# WB32F10x register map
File version: 1.2
CPU: CM3 r2p0, little endian, MPU, no FPU, 4 interrupt priority bits
Registers are 32-bit, read-write, reset 0x0 unless marked. A register's access mark holds for its fields unless they carry their own. Offsets are from the block's base; [hi:lo] are bit positions; 'fields as' and 'values as' point back to an identical list.

## I2C1 — Inter-Integrated Circuit 1
Base 0x40008800
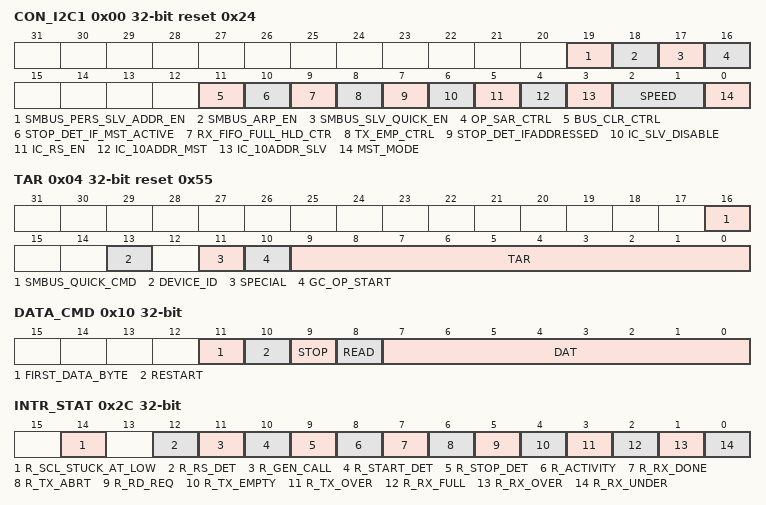
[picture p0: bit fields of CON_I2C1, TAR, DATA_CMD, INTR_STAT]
0x00 CON_I2C1 reset 0x24 — Control register for I2C1
  [19] SMBUS_PERS_SLV_ADDR_EN — SMBUS PSA enable
  [18] SMBUS_ARP_EN — SMBUS ARP enable
  [17] SMBUS_SLV_QUICK_EN — SMBUS slave quick command enable
  [16] OP_SAR_CTRL — Optional slave address control
  [11] BUS_CLR_CTRL — Bus clear control
  [10] STOP_DET_IF_MST_ACTIVE — STOP_DET interrupt enable when master is active
  [9] RX_FIFO_FULL_HLD_CTR — Hold bus when receive FIFO full control bit
  [8] TX_EMP_CTRL — Transmit empty control
  [7] STOP_DET_IFADDRESSED — STOP_DET interrupt enable when slave is addressed
  [6] IC_SLV_DISABLE — I2C slave mode disable
  [5] IC_RS_EN — I2C restart enable
  [4] IC_10ADDR_MST — I2C master 10 bits address selection
  [3] IC_10ADDR_SLV — I2C slave 10 bits address selection
  [2:1] SPEED — I2C transfer speed
  [0] MST_MODE — Master mode enable
0x04 TAR reset 0x55 — Target register
  [16] SMBUS_QUICK_CMD — SMBUS QUICK_CMD enable
  [13] DEVICE_ID — Enable DEVICE_ID
  [11] SPECIAL — Enable DEVICE_ID,GENERAL_CALL and START transfer
  [10] GC_OP_START — GENERAL CALL or START optional
  [9:0] TAR — Target address
0x08 SAR reset 0x3F0 — Slave address register
  [9:0] SAR — Slave address
0x0C HS_MADDR reset 0x1 — High speed master address register
  [2:0] HS_MAR — Master address in high speed
0x10 DATA_CMD — I2C data and command register
  [11] FIRST_DATA_BYTE
  [10] RESTART — Send restart command after transmitting
  [9] STOP — Send stop command after transmitting or receiving
  [8] READ — Master send read command
  [7:0] DAT — Data of I2C bus
0x14 SS_SCL_HCNT reset 0x320 — Standard speed clock high counter register
  [15:0] IC_SS_SCL_HCNT — SCL high level time in I2C standard speed mode
0x18 SS_SCL_LCNT reset 0x3AC — Standard speed clock low counter register
  [15:0] IC_SS_SCL_LCNT — SCL low level time in I2C standard speed mode
0x1C FS_SCL_HCNT reset 0x78 — Fast speed clock high counter register
  [15:0] IC_FS_SCL_HCNT — SCL high level time in I2C fast speed mode
0x20 FS_SCL_LCNT reset 0x104 — Fast speed clock low counter register
  [15:0] IC_FS_SCL_LCNT — SCL low level time in I2C fast speed mode
0x24 HS_SCL_HCNT reset 0xC — High speed clock high counter register
  [15:0] IC_HS_SCL_HCNT — SCL high level time in I2C high speed mode
0x28 HS_SCL_LCNT reset 0x20 — High speed clock low counter register
  [15:0] IC_HS_SCL_LCNT — SCL low level time in I2C high speed mode
0x2C INTR_STAT ro — I2C interrupt state register
  [14] R_SCL_STUCK_AT_LOW — R_SCL_STUCK_AT_LOW interrupt state
  [12] R_RS_DET — R_RS_DET interrupt state
  [11] R_GEN_CALL — R_GEN_CALL interrupt state
  [10] R_START_DET — R_START_DET interrupt state
  [9] R_STOP_DET — R_STOP_DET interrupt state
  [8] R_ACTIVITY — R_ACTIVITY interrupt state
  [7] R_RX_DONE — R_RX_DONE interrupt state
  [6] R_TX_ABRT — R_TX_ABRT interrupt state
  [5] R_RD_REQ — R_RD_REQ interrupt state
  [4] R_TX_EMPTY — R_TX_EMPTY interrupt state
  [3] R_TX_OVER — R_TX_OVER interrupt state
  [2] R_RX_FULL — R_RX_FULL interrupt state
  [1] R_RX_OVER — R_RX_OVER interrupt state
  [0] R_RX_UNDER — R_RX_UNDER interrupt state
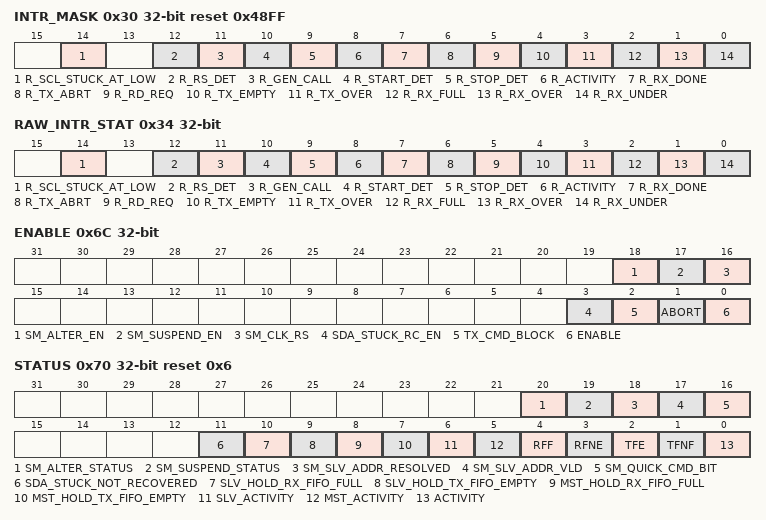
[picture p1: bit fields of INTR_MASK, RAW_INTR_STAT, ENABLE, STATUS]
0x30 INTR_MASK reset 0x48FF — I2C interrupt mask register
  [14] R_SCL_STUCK_AT_LOW — R_SCL_STUCK_AT_LOW interrupt mask
  [12] R_RS_DET — R_RS_DET interrupt mask
  [11] R_GEN_CALL — R_GEN_CALL interrupt mask
  [10] R_START_DET — R_START_DET interrupt mask
  [9] R_STOP_DET — R_STOP_DET interrupt mask
  [8] R_ACTIVITY — R_ACTIVITY interrupt mask
  [7] R_RX_DONE — R_RX_DONE interrupt mask
  [6] R_TX_ABRT — R_TX_ABRT interrupt mask
  [5] R_RD_REQ — R_RD_REQ interrupt mask
  [4] R_TX_EMPTY — R_TX_EMPTY interrupt mask
  [3] R_TX_OVER — R_TX_OVER interrupt mask
  [2] R_RX_FULL — R_RX_FULL interrupt mask
  [1] R_RX_OVER — R_RX_OVER interrupt mask
  [0] R_RX_UNDER — R_RX_UNDER interrupt mask
0x34 RAW_INTR_STAT ro — I2C raw interrupt state register
  [14] R_SCL_STUCK_AT_LOW — R_SCL_STUCK_AT_LOW interrupt raw state
  [12] R_RS_DET — R_RS_DET interrupt raw state
  [11] R_GEN_CALL — R_GEN_CALL interrupt raw state
  [10] R_START_DET — R_START_DET interrupt raw state
  [9] R_STOP_DET — R_STOP_DET interrupt raw state
  [8] R_ACTIVITY — R_ACTIVITY interrupt raw state
  [7] R_RX_DONE — R_RX_DONE interrupt raw state
  [6] R_TX_ABRT — R_TX_ABRT interrupt raw state
  [5] R_RD_REQ — R_RD_REQ interrupt raw state
  [4] R_TX_EMPTY — R_TX_EMPTY interrupt raw state
  [3] R_TX_OVER — R_TX_OVER interrupt raw state
  [2] R_RX_FULL — R_RX_FULL interrupt raw state
  [1] R_RX_OVER — R_RX_OVER interrupt raw state
  [0] R_RX_UNDER — R_RX_UNDER interrupt raw state
0x38 RX_TL reset 0x5 — Receive buffer threshold register
  [7:0] RX_TL — Receive buffer threshold
0x3C TX_TL reset 0x5 — Transmit buffer threshold register
  [7:0] TX_TL — Transmit buffer threshold
0x40 CLR_INTR ro — Clear interrupt register
  [0] CLR_INTR — Clear all interrupt states when read this bit
0x44 CLR_RX_UNDER ro — Clear RX_UNDER interrupt register
  [0] CLR_RX_UNDER — Clear RX_UNDER interrupt when read this bit
0x48 CLR_RX_OVER ro — Clear RX_OVER interrupt register
  [0] CLR_RX_OVER — Clear RX_OVER interrupt when read this bit
0x4C CLR_TX_OVER ro — Clear TX_OVER interrupt register
  [0] CLR_RX_OVER — Clear TX_OVER interrupt when read this bit
0x50 CLR_RD_REQ ro — Clear RD_REQ interrupt register
  [0] CLR_RD_REQ — Clear RD_REQ interrupt when read this bit
0x54 CLR_TX_ABRT ro — Clear TX_ABRT interrupt register
  [0] CLR_TX_ABRT — Clear TX_ABRT interrupt when read this bit
0x58 CLR_RX_DONE ro — Clear RX_DONE interrupt register
  [0] CLR_RX_DONE — Clear RX_DONE interrupt when read this bit
0x5C CLR_ACTIVITY ro — Clear TX_OVER interrupt register
  [0] CLR_ACTIVITY — Clear ACTIVITY interrupt when read this bit and I2C is not in active state
0x60 CLR_STOP_DET ro — Clear STOP_DET interrupt register
  [0] CLR_STOP_DET — Clear STOP_DET interrupt when read this bit
0x64 CLR_START_DET ro — Clear START_DET interrupt register
  [0] CLR_START_DET — Clear START_DET interrupt when read this bit
0x68 CLR_GEN_CALL ro — Clear GEN_CALL interrupt register
  [0] CLR_GEN_CALL — Clear GEN_CALL interrupt when read this bit
0x6C ENABLE — I2C enable register
  [18] SM_ALTER_EN — SMBUS alerter enable
  [17] SM_SUSPEND_EN — SMBUS suspend enable
  [16] SM_CLK_RS — SMBUS clock reset
  [3] SDA_STUCK_RC_EN — Recover SDA bus enable when SDA bus stuck in low level
  [2] TX_CMD_BLOCK — Block I2C bus transfer
  [1] ABORT — Abort transfer in master mode by setting this bit
  [0] ENABLE — Enable I2C
0x70 STATUS ro reset 0x6 — I2C status register
  [20] SM_ALTER_STATUS — SMBUS alerter satus
  [19] SM_SUSPEND_STATUS — SMBUS suspend status
  [18] SM_SLV_ADDR_RESOLVED — SMBUS slave address resolved
  [17] SM_SLV_ADDR_VLD — SMBUS slave address valuable
  [16] SM_QUICK_CMD_BIT — SMBUS QUICK CMD control
  [11] SDA_STUCK_NOT_RECOVERED — SDA status after recover
  [10] SLV_HOLD_RX_FIFO_FULL — Slave hold bus when receive FIFO is full
  [9] SLV_HOLD_TX_FIFO_EMPTY — Slave hold bus when transmit FIFO is empty
  [8] MST_HOLD_RX_FIFO_FULL — Master hold bus when receive FIFO is full
  [7] MST_HOLD_TX_FIFO_EMPTY — Master hold bus when transmit FIFO is empty
  [6] SLV_ACTIVITY — Slave activity status
  [5] MST_ACTIVITY — Master activity status
  [4] RFF — Receive buffer full
  [3] RFNE — Receive buffer not empty
  [2] TFE — Transmit buffer empty
  [1] TFNF — Transmit buffer not full
  [0] ACTIVITY — I2C activity status
0x74 TXFLR ro — Transmit buffer level register
  [2:0] TXFLR — Data numbers of transmit buffer
0x78 RXFLR ro — Receive buffer level register
  [2:0] RXFLR — Data numbers of Receive buffer
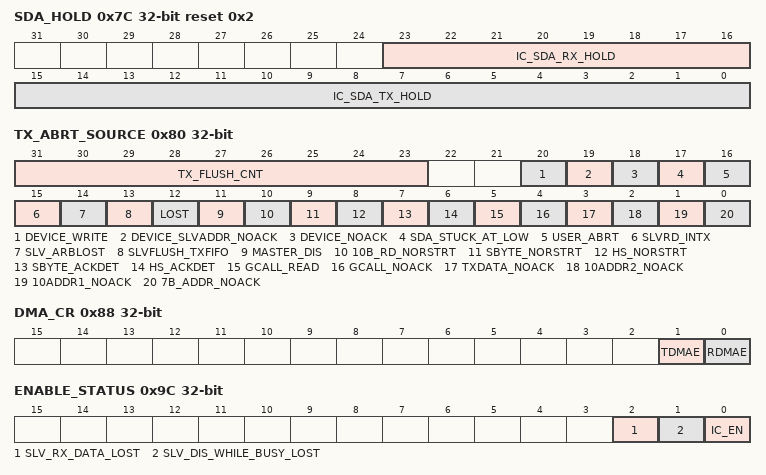
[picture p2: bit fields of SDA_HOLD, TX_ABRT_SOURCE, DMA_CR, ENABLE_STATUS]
0x7C SDA_HOLD reset 0x2
  [23:16] IC_SDA_RX_HOLD — SDA hold time in receive mode
  [15:0] IC_SDA_TX_HOLD — SDA hold time in transmit mode
0x80 TX_ABRT_SOURCE ro — Transmit abort source register
  [31:23] TX_FLUSH_CNT — Number of data lost because of TX_ABRT interrupt
  [20] DEVICE_WRITE — Other commands remain in Transmit FIFO when master start a DEVICE_ID transfer
  [19] DEVICE_SLVADDR_NOACK — No ACK from addressed slave for master's DEVICE_ID transfer
  [18] DEVICE_NOACK — No ACK for master's DEVICE_ID transfer
  [17] SDA_STUCK_AT_LOW — SDA stucks at low level for several ic_clk cycles which is specified in related register
  [16] USER_ABRT — Transfer abort
  [15] SLVRD_INTX — Write 1 into DATA_CMD.READ when slave receive a read request from master
  [14] SLV_ARBLOST — BUS arbitration lost when slave is transmitting
  [13] SLVFLUSH_TXFIFO — Data remains in transmit FIFO when slave receive a read request
  [12] LOST — BUS arbitration failure
  [11] MASTER_DIS — Master is disable when asked to transmit
  [10] 10B_RD_NORSTRT — Read data in 10 bits address mode when RESTART is disable
  [9] SBYTE_NORSTRT — RESTART is disable when master is sending START
  [8] HS_NORSTRT — RESTART is disable when master is switching to HS mode
  [7] SBYTE_ACKDET — ACK for master's sending START
  [6] HS_ACKDET — ACK for master's sending HS code
  [5] GCALL_READ — READ command after sending GCALL
  [4] GCALL_NOACK — No ACK for sending GCALL
  [3] TXDATA_NOACK — No ACK for transmitting data
  [2] 10ADDR2_NOACK — No ACK for second address byte in 10 bits address mode
  [1] 10ADDR1_NOACK — No ACK for first address byte in 10 bits address mode
  [0] 7B_ADDR_NOACK — No ACK in 7 bits address mode
0x84 SLV_DATA_NACK_ONLY — Slave data NACK register
  [0] NACK — Generate NACK
0x88 DMA_CR — DMA control register
  [1] TDMAE — Transmit DMA enable
  [0] RDMAE — Receive DMA enable
0x8C DMA_TDLR — DMA transmit data level register
  [2:0] DMATDL — DMA transmit data level
0x90 DMA_RDLR — DMA receive data level register
  [2:0] DMARDL — DMA receive data level
0x94 SDA_SETUP — SDA set-up time register
  [7:0] SDA_SETUP — SDA set-up time
0x98 ACK_GENERAL_CALL reset 0x64
  [0] ACK_GENERAL_CALL — ACK/NACK for a general all
0x9C ENABLE_STATUS ro
  [2] SLV_RX_DATA_LOST — Slave lost receive data
  [1] SLV_DIS_WHILE_BUSY_LOST — Slave disable while busy lost
  [0] IC_EN — I2C enable status
0xA0 FS_SPKLEN1 reset 0x1 — Fast speed spike length register for I2C1
  [7:0] IC_FS_SPKLEN — Max spike value on SCL and SDA line in standard and fast speed mode
0xA4 HS_SPKLEN reset 0x1 — High speed spike length register
  [7:0] IC_FS_SPKLEN — Max spike value on SCL and SDA line in high speed mode
0xA8 CLR_RESTART_DET ro — Clear RESTART_DET interrupt register
  [0] CLR_RS_DET — Clear RESTART_DET interrupt when user reads this bit
0xAC SCL_STUCK_AT_LOW_TIMEOUT reset 0xFFFFFFFF — SCl stuck at low level timeout register
  [31:0] SCL_LOWTO — Timeout threshold for SCL_STUCK_AT_LOW interrupt
0xB0 SDA_STUCK_AT_LOW_TIMEOUT reset 0xFFFFFFFF — SDA stuck at low level timeout register
  [31:0] SDA_LOWTO — Timeout threshold for SDA
0xBC SMBUS_CLK_LOW_SEXT reset 0xFFFFFFFF — SMBUS clock low slave extend timeout register
  [31:0] SMBUS_CLK_LOW_SEXT_TO — Define a paragram of SMBUS
0xC0 SMBUS_CLK_LOW_MEXT reset 0xFFFFFFFF — SMBUS clock low master extend timeout register
  [31:0] SMBUS_CLK_LOW_MEXT_TO — Define a paragram of SMBUS
0xC4 SMBUS_THIGH_MAX_IDLE_COUNT reset 0xFFFF — SMBUS master tight max bus-idle count register
  [15:0] SMBUS_MBI_CNT — Define SMBUS max idle time
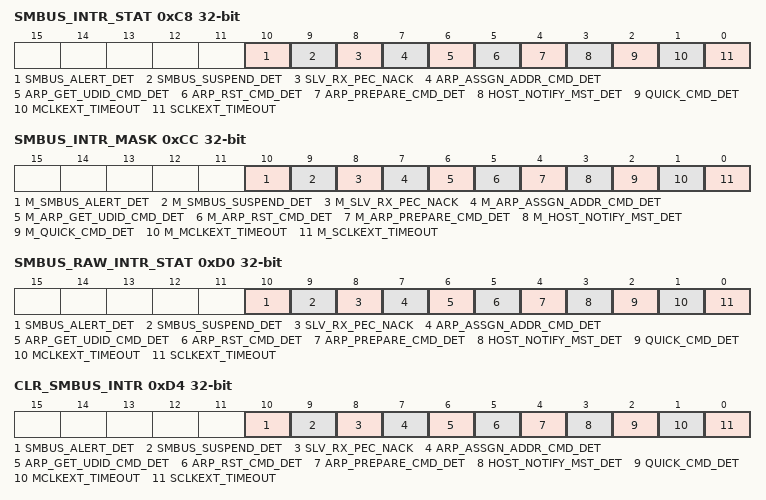
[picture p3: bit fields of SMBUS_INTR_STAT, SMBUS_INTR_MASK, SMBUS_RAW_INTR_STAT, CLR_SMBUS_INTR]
0xC8 SMBUS_INTR_STAT ro — SMBUS interrupt state register
  [10] SMBUS_ALERT_DET — SMBUS_ALERT_DET interrupt state
  [9] SMBUS_SUSPEND_DET — SMBUS_SUSPEND_DET interrupt state
  [8] SLV_RX_PEC_NACK — SLV_RX_PEC_NACK interrupt state
  [7] ARP_ASSGN_ADDR_CMD_DET — ARP_ASSGN_ADDR_CMD_DET interrupt state
  [6] ARP_GET_UDID_CMD_DET — ARP_GET_UDID_CMD_DET interrupt state
  [5] ARP_RST_CMD_DET — ARP_RST_CMD_DET interrupt state
  [4] ARP_PREPARE_CMD_DET — ARP_PREPARE_CMD_DET interrupt state
  [3] HOST_NOTIFY_MST_DET — HOST_NOTIFY_MST_DET interrupt state
  [2] QUICK_CMD_DET — QUICK_CMD_DET interrupt state
  [1] MCLKEXT_TIMEOUT — MCLKEXT_TIMEOUT interrupt state
  [0] SCLKEXT_TIMEOUT — SCLKEXT_TIMEOUT interrupt state
0xCC SMBUS_INTR_MASK — SMBUS interrupt mask register
  [10] M_SMBUS_ALERT_DET — SMBUS_ALERT_DET interrupt mask
  [9] M_SMBUS_SUSPEND_DET — SMBUS_SUSPEND_DET interrupt mask
  [8] M_SLV_RX_PEC_NACK — SLV_RX_PEC_NACK interrupt mask
  [7] M_ARP_ASSGN_ADDR_CMD_DET — ARP_ASSGN_ADDR_CMD_DET interrupt mask
  [6] M_ARP_GET_UDID_CMD_DET — ARP_GET_UDID_CMD_DET interrupt mask
  [5] M_ARP_RST_CMD_DET — ARP_RST_CMD_DET interrupt mask
  [4] M_ARP_PREPARE_CMD_DET — ARP_PREPARE_CMD_DET interrupt mask
  [3] M_HOST_NOTIFY_MST_DET — HOST_NOTIFY_MST_DET interrupt mask
  [2] M_QUICK_CMD_DET — QUICK_CMD_DET interrupt mask
  [1] M_MCLKEXT_TIMEOUT — MCLKEXT_TIMEOUT interrupt mask
  [0] M_SCLKEXT_TIMEOUT — SCLKEXT_TIMEOUT interrupt mask
0xD0 SMBUS_RAW_INTR_STAT ro — SMBUS raw interrupt state register
  [10] SMBUS_ALERT_DET — SMBUS_ALERT_DET raw interrupt state
  [9] SMBUS_SUSPEND_DET — SMBUS_SUSPEND_DET raw interrupt state
  [8] SLV_RX_PEC_NACK — SLV_RX_PEC_NACK raw interrupt state
  [7] ARP_ASSGN_ADDR_CMD_DET — ARP_ASSGN_ADDR_CMD_DET raw interrupt state
  [6] ARP_GET_UDID_CMD_DET — ARP_GET_UDID_CMD_DET raw interrupt state
  [5] ARP_RST_CMD_DET — ARP_RST_CMD_DET raw interrupt state
  [4] ARP_PREPARE_CMD_DET — ARP_PREPARE_CMD_DET raw interrupt state
  [3] HOST_NOTIFY_MST_DET — HOST_NOTIFY_MST_DET raw interrupt state
  [2] QUICK_CMD_DET — QUICK_CMD_DET raw interrupt state
  [1] MCLKEXT_TIMEOUT — MCLKEXT_TIMEOUT raw interrupt state
  [0] SCLKEXT_TIMEOUT — SCLKEXT_TIMEOUT raw interrupt state
0xD4 CLR_SMBUS_INTR wo — Clear SMBUS interrupt register
  [10] SMBUS_ALERT_DET — Clear SMBUS_ALERT_DET interrupt state
  [9] SMBUS_SUSPEND_DET — Clear SMBUS_SUSPEND_DET interrupt state
  [8] SLV_RX_PEC_NACK — Clear SLV_RX_PEC_NACK interrupt state
  [7] ARP_ASSGN_ADDR_CMD_DET — Clear ARP_ASSGN_ADDR_CMD_DET interrupt state
  [6] ARP_GET_UDID_CMD_DET — Clear ARP_GET_UDID_CMD_DET interrupt state
  [5] ARP_RST_CMD_DET — Clear ARP_RST_CMD_DET interrupt state
  [4] ARP_PREPARE_CMD_DET — Clear ARP_PREPARE_CMD_DET interrupt state
  [3] HOST_NOTIFY_MST_DET — Clear HOST_NOTIFY_MST_DET interrupt state
  [2] QUICK_CMD_DET — Clear QUICK_CMD_DET interrupt state
  [1] MCLKEXT_TIMEOUT — Clear MCLKEXT_TIMEOUT interrupt state
  [0] SCLKEXT_TIMEOUT — Clear SCLKEXT_TIMEOUT interrupt state
0xD8 OPTIONAL_SAR — Optional slave address register
  [6:0] OPTIONAL_SAR — Optional slave address
0xDC SMBUS_UDID_LSB ro reset 0xFFFFFFFF
  [31:0] SMBUS_UDID_LSB — LSB 32 bits of SMBUS UDID

## I2C2 — Inter-Integrated Circuit 2
Base 0x40008C00
Registers as I2C1 (with I2C1 read as I2C2), without FS_SPKLEN1; these are added or differ:
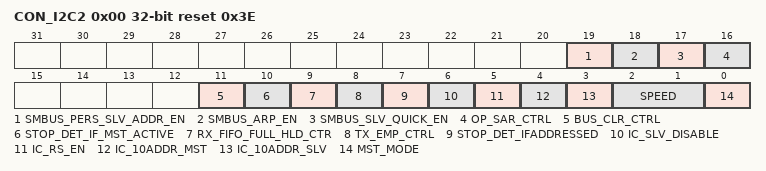
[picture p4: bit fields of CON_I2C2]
0x00 CON_I2C2 reset 0x3E (alternate view of CON_I2C1) — Control register for I2C2
  fields as I2C1.CON_I2C1
0xA0 FS_SPKLEN2 reset 0x5 (alternate view of FS_SPKLEN1) — Fast speed spike length register for I2C2
  [7:0] IC_FS_SPKLEN — Max spike value on SCL and SDA line in standard and fast speed mode
